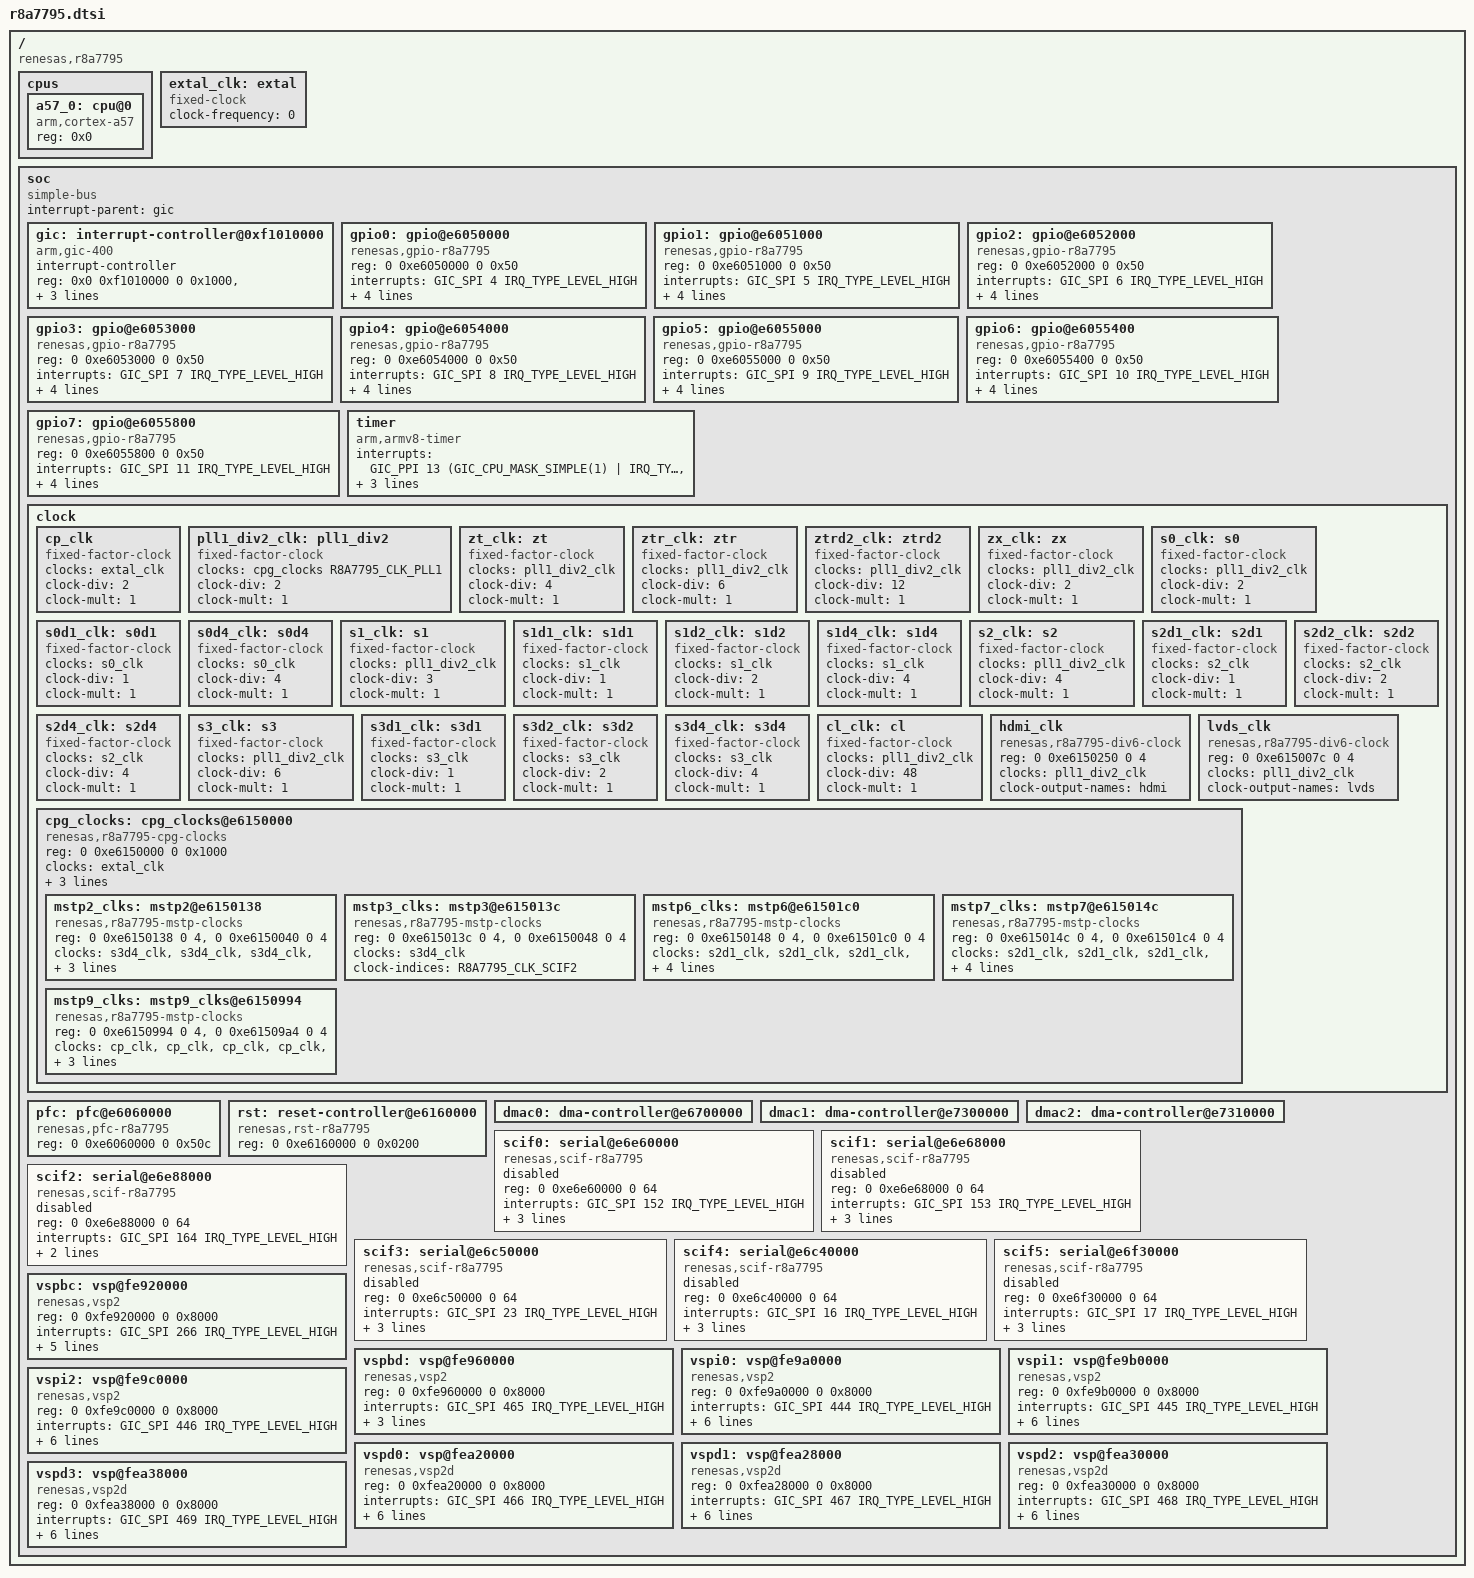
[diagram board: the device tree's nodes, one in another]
/*
 * Device Tree Source for the r8a7795 SoC
 *
 * Copyright (C) 2015 Renesas Electronics Corp.
 *
 * This file is licensed under the terms of the GNU General Public License
 * version 2.  This program is licensed "as is" without any warranty of any
 * kind, whether express or implied.
 */

#include <dt-bindings/clock/r8a7795-clock.h>
#include <dt-bindings/interrupt-controller/arm-gic.h>

/ {
	compatible = "renesas,r8a7795";
	#address-cells = <2>;
	#size-cells = <2>;

	cpus {
		#address-cells = <1>;
		#size-cells = <0>;

		/* 1core only at this point */
		a57_0: cpu@0 {
			compatible = "arm,cortex-a57", "arm,armv8";
			reg = <0x0>;
			device_type = "cpu";
		};
	};

	extal_clk: extal {
		compatible = "fixed-clock";
		#clock-cells = <0>;
		clock-frequency = <0>;
	};

	soc {
		compatible = "simple-bus";
		interrupt-parent = <&gic>;
		#address-cells = <2>;
		#size-cells = <2>;
		ranges;

		gic: interrupt-controller@0xf1010000 {
			compatible = "arm,gic-400";
			#interrupt-cells = <3>;
			#address-cells = <0>;
			interrupt-controller;
			reg = <0x0 0xf1010000 0 0x1000>,
			      <0x0 0xf1020000 0 0x2000>;
			interrupts = <GIC_PPI 9
					(GIC_CPU_MASK_SIMPLE(1) | IRQ_TYPE_LEVEL_HIGH)>;
		};

		gpio0: gpio@e6050000 {
			compatible = "renesas,gpio-r8a7795",
				     "renesas,gpio-rcar";
			reg = <0 0xe6050000 0 0x50>;
			interrupts = <GIC_SPI 4 IRQ_TYPE_LEVEL_HIGH>;
			#gpio-cells = <2>;
			gpio-controller;
			gpio-ranges = <&pfc 0 0 32>;
			#interrupt-cells = <2>;
			interrupt-controller;
			clocks = <&mstp9_clks R8A7795_CLK_GPIO0>;
		};

		gpio1: gpio@e6051000 {
			compatible = "renesas,gpio-r8a7795",
				     "renesas,gpio-rcar";
			reg = <0 0xe6051000 0 0x50>;
			interrupts = <GIC_SPI 5 IRQ_TYPE_LEVEL_HIGH>;
			#gpio-cells = <2>;
			gpio-controller;
			gpio-ranges = <&pfc 0 32 32>;
			#interrupt-cells = <2>;
			interrupt-controller;
			clocks = <&mstp9_clks R8A7795_CLK_GPIO1>;
		};

		gpio2: gpio@e6052000 {
			compatible = "renesas,gpio-r8a7795",
				     "renesas,gpio-rcar";
			reg = <0 0xe6052000 0 0x50>;
			interrupts = <GIC_SPI 6 IRQ_TYPE_LEVEL_HIGH>;
			#gpio-cells = <2>;
			gpio-controller;
			gpio-ranges = <&pfc 0 64 32>;
			#interrupt-cells = <2>;
			interrupt-controller;
			clocks = <&mstp9_clks R8A7795_CLK_GPIO2>;
		};

		gpio3: gpio@e6053000 {
			compatible = "renesas,gpio-r8a7795",
				     "renesas,gpio-rcar";
			reg = <0 0xe6053000 0 0x50>;
			interrupts = <GIC_SPI 7 IRQ_TYPE_LEVEL_HIGH>;
			#gpio-cells = <2>;
			gpio-controller;
			gpio-ranges = <&pfc 0 96 32>;
			#interrupt-cells = <2>;
			interrupt-controller;
			clocks = <&mstp9_clks R8A7795_CLK_GPIO3>;
		};

		gpio4: gpio@e6054000 {
			compatible = "renesas,gpio-r8a7795",
				     "renesas,gpio-rcar";
			reg = <0 0xe6054000 0 0x50>;
			interrupts = <GIC_SPI 8 IRQ_TYPE_LEVEL_HIGH>;
			#gpio-cells = <2>;
			gpio-controller;
			gpio-ranges = <&pfc 0 128 32>;
			#interrupt-cells = <2>;
			interrupt-controller;
			clocks = <&mstp9_clks R8A7795_CLK_GPIO4>;
		};

		gpio5: gpio@e6055000 {
			compatible = "renesas,gpio-r8a7795",
				     "renesas,gpio-rcar";
			reg = <0 0xe6055000 0 0x50>;
			interrupts = <GIC_SPI 9 IRQ_TYPE_LEVEL_HIGH>;
			#gpio-cells = <2>;
			gpio-controller;
			gpio-ranges = <&pfc 0 160 32>;
			#interrupt-cells = <2>;
			interrupt-controller;
			clocks = <&mstp9_clks R8A7795_CLK_GPIO5>;
		};

		gpio6: gpio@e6055400 {
			compatible = "renesas,gpio-r8a7795",
				     "renesas,gpio-rcar";
			reg = <0 0xe6055400 0 0x50>;
			interrupts = <GIC_SPI 10 IRQ_TYPE_LEVEL_HIGH>;
			#gpio-cells = <2>;
			gpio-controller;
			gpio-ranges = <&pfc 0 192 32>;
			#interrupt-cells = <2>;
			interrupt-controller;
			clocks = <&mstp9_clks R8A7795_CLK_GPIO6>;
		};

		gpio7: gpio@e6055800 {
			compatible = "renesas,gpio-r8a7795",
				     "renesas,gpio-rcar";
			reg = <0 0xe6055800 0 0x50>;
			interrupts = <GIC_SPI 11 IRQ_TYPE_LEVEL_HIGH>;
			#gpio-cells = <2>;
			gpio-controller;
			gpio-ranges = <&pfc 0 224 32>;
			#interrupt-cells = <2>;
			interrupt-controller;
			clocks = <&mstp9_clks R8A7795_CLK_GPIO7>;
		};

		timer {
			compatible = "arm,armv8-timer";
			interrupts = <GIC_PPI 13
					(GIC_CPU_MASK_SIMPLE(1) | IRQ_TYPE_LEVEL_LOW)>,
				     <GIC_PPI 14
					(GIC_CPU_MASK_SIMPLE(1) | IRQ_TYPE_LEVEL_LOW)>,
				     <GIC_PPI 11
					(GIC_CPU_MASK_SIMPLE(1) | IRQ_TYPE_LEVEL_LOW)>,
				     <GIC_PPI 10
					(GIC_CPU_MASK_SIMPLE(1) | IRQ_TYPE_LEVEL_LOW)>;
		};

		clock {
			#address-cells = <2>;
			#size-cells = <2>;
			#clock-cells = <1>;
			ranges;

			/* Fixed factor clocks */
			cp_clk: cp_clk {
				compatible = "fixed-factor-clock";
				clocks = <&extal_clk>;
				#clock-cells = <0>;
				clock-div = <2>;
				clock-mult = <1>;
			};

			pll1_div2_clk: pll1_div2 {
				compatible = "fixed-factor-clock";
				clocks = <&cpg_clocks R8A7795_CLK_PLL1>;
				#clock-cells = <0>;
				clock-div = <2>;
				clock-mult = <1>;
			};

			zt_clk: zt {
				compatible = "fixed-factor-clock";
				clocks = <&pll1_div2_clk>;
				#clock-cells = <0>;
				clock-div = <4>;
				clock-mult = <1>;
			};

			ztr_clk: ztr {
				compatible = "fixed-factor-clock";
				clocks = <&pll1_div2_clk>;
				#clock-cells = <0>;
				clock-div = <6>;
				clock-mult = <1>;
			};

			ztrd2_clk: ztrd2 {
				compatible = "fixed-factor-clock";
				clocks = <&pll1_div2_clk>;
				#clock-cells = <0>;
				clock-div = <12>;
				clock-mult = <1>;
			};

			zx_clk: zx {
				compatible = "fixed-factor-clock";
				clocks = <&pll1_div2_clk>;
				#clock-cells = <0>;
				clock-div = <2>;
				clock-mult = <1>;
			};

			s0_clk: s0 {
				compatible = "fixed-factor-clock";
				clocks = <&pll1_div2_clk>;
				#clock-cells = <0>;
				clock-div = <2>;
				clock-mult = <1>;
			};

			s0d1_clk: s0d1 {
				compatible = "fixed-factor-clock";
				clocks = <&s0_clk>;
				#clock-cells = <0>;
				clock-div = <1>;
				clock-mult = <1>;
			};

			s0d4_clk: s0d4 {
				compatible = "fixed-factor-clock";
				clocks = <&s0_clk>;
				#clock-cells = <0>;
				clock-div = <4>;
				clock-mult = <1>;
			};

			s1_clk: s1 {
				compatible = "fixed-factor-clock";
				clocks = <&pll1_div2_clk>;
				#clock-cells = <0>;
				clock-div = <3>;
				clock-mult = <1>;
			};

			s1d1_clk: s1d1 {
				compatible = "fixed-factor-clock";
				clocks = <&s1_clk>;
				#clock-cells = <0>;
				clock-div = <1>;
				clock-mult = <1>;
			};

			s1d2_clk: s1d2 {
				compatible = "fixed-factor-clock";
				clocks = <&s1_clk>;
				#clock-cells = <0>;
				clock-div = <2>;
				clock-mult = <1>;
			};

			s1d4_clk: s1d4 {
				compatible = "fixed-factor-clock";
				clocks = <&s1_clk>;
				#clock-cells = <0>;
				clock-div = <4>;
				clock-mult = <1>;
			};

			s2_clk: s2 {
				compatible = "fixed-factor-clock";
				clocks = <&pll1_div2_clk>;
				#clock-cells = <0>;
				clock-div = <4>;
				clock-mult = <1>;
			};

			s2d1_clk: s2d1 {
				compatible = "fixed-factor-clock";
				clocks = <&s2_clk>;
				#clock-cells = <0>;
				clock-div = <1>;
				clock-mult = <1>;
			};

			s2d2_clk: s2d2 {
				compatible = "fixed-factor-clock";
				clocks = <&s2_clk>;
				#clock-cells = <0>;
				clock-div = <2>;
				clock-mult = <1>;
			};

			s2d4_clk: s2d4 {
				compatible = "fixed-factor-clock";
				clocks = <&s2_clk>;
				#clock-cells = <0>;
				clock-div = <4>;
				clock-mult = <1>;
			};

			s3_clk: s3 {
				compatible = "fixed-factor-clock";
				clocks = <&pll1_div2_clk>;
				#clock-cells = <0>;
				clock-div = <6>;
				clock-mult = <1>;
			};

			s3d1_clk: s3d1 {
				compatible = "fixed-factor-clock";
				clocks = <&s3_clk>;
				#clock-cells = <0>;
				clock-div = <1>;
				clock-mult = <1>;
			};

			s3d2_clk: s3d2 {
				compatible = "fixed-factor-clock";
				clocks = <&s3_clk>;
				#clock-cells = <0>;
				clock-div = <2>;
				clock-mult = <1>;
			};

			s3d4_clk: s3d4 {
				compatible = "fixed-factor-clock";
				clocks = <&s3_clk>;
				#clock-cells = <0>;
				clock-div = <4>;
				clock-mult = <1>;
			};

			cl_clk: cl {
				compatible = "fixed-factor-clock";
				clocks = <&pll1_div2_clk>;
				#clock-cells = <0>;
				clock-div = <48>;
				clock-mult = <1>;
			};

			hdmi_clk: hdmi_clk {
				compatible = "renesas,r8a7795-div6-clock", "renesas,cpg-div6-clock";
				reg = <0 0xe6150250 0 4>;
				clocks = <&pll1_div2_clk>;
				#clock-cells = <0>;
				clock-output-names = "hdmi";
			};

			lvds_clk: lvds_clk {
				compatible = "renesas,r8a7795-div6-clock", "renesas,cpg-div6-clock";
				reg = <0 0xe615007c 0 4>;
				clocks = <&pll1_div2_clk>;
				#clock-cells = <0>;
				clock-output-names = "lvds";
			};

			cpg_clocks: cpg_clocks@e6150000 {
				#address-cells = <2>;
				#size-cells = <2>;
				#clock-cells = <1>;
				ranges;

				compatible = "renesas,r8a7795-cpg-clocks",
					     "renesas,rcar-gen3-cpg-clocks";
				reg = <0 0xe6150000 0 0x1000>;
				clocks = <&extal_clk>;
				clock-indices = <
					R8A7795_CLK_MAIN R8A7795_CLK_PLL0
					R8A7795_CLK_PLL1 R8A7795_CLK_PLL2
					R8A7795_CLK_PLL3 R8A7795_CLK_PLL4
				>;
				#power-domain-cells = <0>;
				renesas,modemr = <&rst 0x60>;

				mstp2_clks: mstp2@e6150138 {
					compatible =
						"renesas,r8a7795-mstp-clocks",
						"renesas,cpg-mstp-clocks";
					reg = <0 0xe6150138 0 4>,
					      <0 0xe6150040 0 4>;
					clocks = <&s3d4_clk>, <&s3d4_clk>,
						 <&s3d4_clk>, <&s3d4_clk>,
						 <&s3d4_clk>;
					#clock-cells = <1>;
					clock-indices = <
						R8A7795_CLK_SCIF5
						R8A7795_CLK_SCIF4
						R8A7795_CLK_SCIF3
						R8A7795_CLK_SCIF1
						R8A7795_CLK_SCIF0
					>;
				};

				mstp3_clks: mstp3@e615013c {
					compatible = "renesas,r8a7795-mstp-clocks",
					             "renesas,cpg-mstp-clocks";
					reg = <0 0xe615013c 0 4>, <0 0xe6150048 0 4>;
					clocks =  <&s3d4_clk>;
					#clock-cells = <1>;
					clock-indices = <R8A7795_CLK_SCIF2>;
				};

				mstp6_clks: mstp6@e61501c0 {
					compatible = "renesas,r8a7795-mstp-clocks",
						     "renesas,cpg-mstp-clocks";
					reg = <0 0xe6150148 0 4>, <0 0xe61501c0 0 4>;
					clocks =  <
						&s2d1_clk &s2d1_clk &s2d1_clk &s2d1_clk
						&s2d1_clk &s2d1_clk &s2d1_clk &s2d1_clk
						&s2d1_clk
					>;
					#clock-cells = <1>;
					clock-indices = <
						R8A7795_CLK_VSPD3 R8A7795_CLK_VSPD2
						R8A7795_CLK_VSPD1 R8A7795_CLK_VSPD0
						R8A7795_CLK_VSPBC R8A7795_CLK_VSPBD
						R8A7795_CLK_VSPI2 R8A7795_CLK_VSPI1
						R8A7795_CLK_VSPI0
					>;
				};

				mstp7_clks: mstp7@e615014c {
					compatible = "renesas,r8a7795-mstp-clocks",
						     "renesas,cpg-mstp-clocks";
					reg = <0 0xe615014c 0 4>, <0 0xe61501c4 0 4>;
					clocks =  <&s2d1_clk>, <&s2d1_clk>, <&s2d1_clk>,
						  <&s2d1_clk>, <&s2d1_clk>, <&s2d1_clk>,
						  <&lvds_clk>, <&hdmi_clk>, <&hdmi_clk>;
					#clock-cells = <1>;
					clock-indices = <
						R8A7795_CLK_DU3 R8A7795_CLK_DU2
						R8A7795_CLK_DU1 R8A7795_CLK_DU0
						R8A7795_CLK_LVDS R8A7795_CLK_HDMI1
						R8A7795_CLK_HDMI0
					>;
				};

				mstp9_clks: mstp9_clks@e6150994 {
					compatible = "renesas,r8a7795-mstp-clocks",
						     "renesas,cpg-mstp-clocks";
					reg = <0 0xe6150994 0 4>, <0 0xe61509a4 0 4>;
					clocks = <&cp_clk>, <&cp_clk>, <&cp_clk>,
						 <&cp_clk>, <&cp_clk>, <&cp_clk>,
						 <&cp_clk>, <&cp_clk>;
					#clock-cells = <1>;
					clock-indices = <
						R8A7795_CLK_GPIO7 R8A7795_CLK_GPIO6
						R8A7795_CLK_GPIO5 R8A7795_CLK_GPIO4
						R8A7795_CLK_GPIO3 R8A7795_CLK_GPIO2
						R8A7795_CLK_GPIO1 R8A7795_CLK_GPIO0
					>;
				};
			};
		};

		pfc: pfc@e6060000 {
			compatible = "renesas,pfc-r8a7795";
			reg = <0 0xe6060000 0 0x50c>;
		};

		rst: reset-controller@e6160000 {
			compatible = "renesas,rst-r8a7795", "syscon";
			reg = <0 0xe6160000 0 0x0200>;
		};

		dmac0: dma-controller@e6700000 {
			/* Empty node for now */
		};

		dmac1: dma-controller@e7300000 {
			/* Empty node for now */
		};

		dmac2: dma-controller@e7310000 {
			/* Empty node for now */
		};

		scif0: serial@e6e60000 {
			compatible = "renesas,scif-r8a7795", "renesas,scif";
			reg = <0 0xe6e60000 0 64>;
			interrupts = <GIC_SPI 152 IRQ_TYPE_LEVEL_HIGH>;
			clocks = <&mstp2_clks R8A7795_CLK_SCIF0>;
			clock-names = "sci_ick";
			dmas = <&dmac1 0x51>, <&dmac1 0x50>;
			dma-names = "tx", "rx";
			power-domains = <&cpg_clocks>;
			status = "disabled";
		};

		scif1: serial@e6e68000 {
			compatible = "renesas,scif-r8a7795", "renesas,scif";
			reg = <0 0xe6e68000 0 64>;
			interrupts = <GIC_SPI 153 IRQ_TYPE_LEVEL_HIGH>;
			clocks = <&mstp2_clks R8A7795_CLK_SCIF1>;
			clock-names = "sci_ick";
			dmas = <&dmac1 0x53>, <&dmac1 0x52>;
			dma-names = "tx", "rx";
			power-domains = <&cpg_clocks>;
			status = "disabled";
		};

		scif2: serial@e6e88000 {
			compatible = "renesas,scif-r8a7795", "renesas,scif";
			reg = <0 0xe6e88000 0 64>;
			interrupts = <GIC_SPI 164 IRQ_TYPE_LEVEL_HIGH>;
			clocks = <&mstp3_clks R8A7795_CLK_SCIF2>;
			clock-names = "sci_ick";
			power-domains = <&cpg_clocks>;
			status = "disabled";
		};

		scif3: serial@e6c50000 {
			compatible = "renesas,scif-r8a7795", "renesas,scif";
			reg = <0 0xe6c50000 0 64>;
			interrupts = <GIC_SPI 23 IRQ_TYPE_LEVEL_HIGH>;
			clocks = <&mstp2_clks R8A7795_CLK_SCIF3>;
			clock-names = "sci_ick";
			dmas = <&dmac0 0x57>, <&dmac0 0x56>;
			dma-names = "tx", "rx";
			power-domains = <&cpg_clocks>;
			status = "disabled";
		};

		scif4: serial@e6c40000 {
			compatible = "renesas,scif-r8a7795", "renesas,scif";
			reg = <0 0xe6c40000 0 64>;
			interrupts = <GIC_SPI 16 IRQ_TYPE_LEVEL_HIGH>;
			clocks = <&mstp2_clks R8A7795_CLK_SCIF4>;
			clock-names = "sci_ick";
			dmas = <&dmac0 0x59>, <&dmac0 0x58>;
			dma-names = "tx", "rx";
			power-domains = <&cpg_clocks>;
			status = "disabled";
		};

		scif5: serial@e6f30000 {
			compatible = "renesas,scif-r8a7795", "renesas,scif";
			reg = <0 0xe6f30000 0 64>;
			interrupts = <GIC_SPI 17 IRQ_TYPE_LEVEL_HIGH>;
			clocks = <&mstp2_clks R8A7795_CLK_SCIF5>;
			clock-names = "sci_ick";
			dmas = <&dmac1 0x5b>, <&dmac1 0x5a>;
			dma-names = "tx", "rx";
			power-domains = <&cpg_clocks>;
			status = "disabled";
		};

		vspbc: vsp@fe920000 {
			compatible = "renesas,vsp2";
			reg = <0 0xfe920000 0 0x8000>;
			interrupts = <GIC_SPI 266 IRQ_TYPE_LEVEL_HIGH>;
			clocks = <&mstp6_clks R8A7795_CLK_VSPBC>;

			renesas,has-lut;
			renesas,has-sru;
			renesas,#rpf = <5>;
			renesas,#wpf = <1>;
		};

		vspbd: vsp@fe960000 {
			compatible = "renesas,vsp2";
			reg = <0 0xfe960000 0 0x8000>;
			interrupts = <GIC_SPI 465 IRQ_TYPE_LEVEL_HIGH>;
			clocks = <&mstp6_clks R8A7795_CLK_VSPBD>;

			renesas,#rpf = <5>;
			renesas,#wpf = <1>;
		};

		vspi0: vsp@fe9a0000 {
			compatible = "renesas,vsp2";
			reg = <0 0xfe9a0000 0 0x8000>;
			interrupts = <GIC_SPI 444 IRQ_TYPE_LEVEL_HIGH>;
			clocks = <&mstp6_clks R8A7795_CLK_VSPI0>;

			renesas,has-lut;
			renesas,has-sru;
			renesas,#rpf = <1>;
			renesas,#uds = <3>;
			renesas,#wpf = <1>;
		};

		vspi1: vsp@fe9b0000 {
			compatible = "renesas,vsp2";
			reg = <0 0xfe9b0000 0 0x8000>;
			interrupts = <GIC_SPI 445 IRQ_TYPE_LEVEL_HIGH>;
			clocks = <&mstp6_clks R8A7795_CLK_VSPI1>;

			renesas,has-lut;
			renesas,has-sru;
			renesas,#rpf = <1>;
			renesas,#uds = <1>;
			renesas,#wpf = <1>;
		};

		vspi2: vsp@fe9c0000 {
			compatible = "renesas,vsp2";
			reg = <0 0xfe9c0000 0 0x8000>;
			interrupts = <GIC_SPI 446 IRQ_TYPE_LEVEL_HIGH>;
			clocks = <&mstp6_clks R8A7795_CLK_VSPI2>;

			renesas,has-lut;
			renesas,has-sru;
			renesas,#rpf = <1>;
			renesas,#uds = <1>;
			renesas,#wpf = <1>;
		};

		vspd0: vsp@fea20000 {
			compatible = "renesas,vsp2d";
			reg = <0 0xfea20000 0 0x8000>;
			interrupts = <GIC_SPI 466 IRQ_TYPE_LEVEL_HIGH>;
			clocks = <&mstp6_clks R8A7795_CLK_VSPD0>;

			renesas,has-bru;
			renesas,has-lif;
			renesas,has-lut;
			renesas,#rpf = <5>;
			renesas,#wpf = <2>;
		};

		vspd1: vsp@fea28000 {
			compatible = "renesas,vsp2d";
			reg = <0 0xfea28000 0 0x8000>;
			interrupts = <GIC_SPI 467 IRQ_TYPE_LEVEL_HIGH>;
			clocks = <&mstp6_clks R8A7795_CLK_VSPD1>;

			renesas,has-bru;
			renesas,has-lif;
			renesas,has-lut;
			renesas,#rpf = <5>;
			renesas,#wpf = <2>;
		};

		vspd2: vsp@fea30000 {
			compatible = "renesas,vsp2d";
			reg = <0 0xfea30000 0 0x8000>;
			interrupts = <GIC_SPI 468 IRQ_TYPE_LEVEL_HIGH>;
			clocks = <&mstp6_clks R8A7795_CLK_VSPD2>;

			renesas,has-bru;
			renesas,has-lif;
			renesas,has-lut;
			renesas,#rpf = <5>;
			renesas,#wpf = <2>;
		};

		vspd3: vsp@fea38000 {
			compatible = "renesas,vsp2d";
			reg = <0 0xfea38000 0 0x8000>;
			interrupts = <GIC_SPI 469 IRQ_TYPE_LEVEL_HIGH>;
			clocks = <&mstp6_clks R8A7795_CLK_VSPD3>;

			renesas,has-bru;
			renesas,has-lif;
			renesas,has-lut;
			renesas,#rpf = <5>;
			renesas,#wpf = <2>;
		};
	};
};
